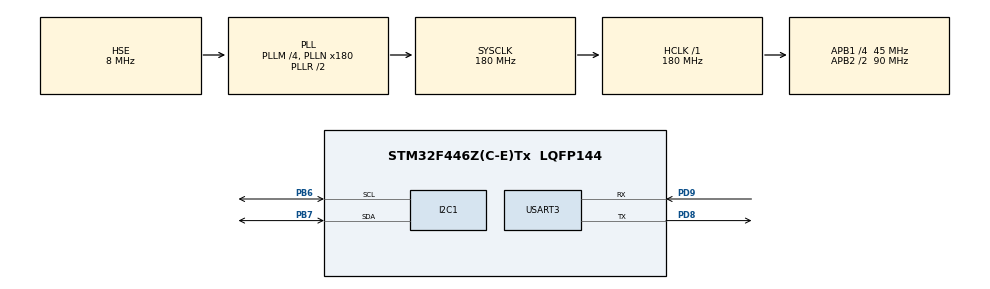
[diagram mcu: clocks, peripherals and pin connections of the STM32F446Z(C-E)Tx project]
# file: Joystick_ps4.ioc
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Mcu.Family=STM32F4
Mcu.Name=STM32F446Z(C-E)Tx
Mcu.Package=LQFP144
NVIC.PriorityGroup=NVIC_PRIORITYGROUP_4
PA13.Mode=Serial_Wire
PA13.Signal=SYS_JTMS-SWDIO
PA14.Mode=Serial_Wire
PA14.Signal=SYS_JTCK-SWCLK
PB6.Mode=I2C
PB6.Signal=I2C1_SCL
PB7.Mode=I2C
PB7.Signal=I2C1_SDA
PC14-OSC32_IN.Mode=LSE-External-Oscillator
PC14-OSC32_IN.Signal=RCC_OSC32_IN
PC15-OSC32_OUT.Mode=LSE-External-Oscillator
PC15-OSC32_OUT.Signal=RCC_OSC32_OUT
PD8.Mode=Asynchronous
PD8.Signal=USART3_TX
PD9.Mode=Asynchronous
PD9.Signal=USART3_RX
PH0-OSC_IN.Mode=HSE-External-Oscillator
PH0-OSC_IN.Signal=RCC_OSC_IN
PH1-OSC_OUT.Mode=HSE-External-Oscillator
PH1-OSC_OUT.Signal=RCC_OSC_OUT
ProjectManager.HeapSize=0x200
ProjectManager.StackSize=0x400
ProjectManager.TargetToolchain=STM32CubeIDE
RCC.48MHZClocksFreq_Value=24000000
RCC.AHBFreq_Value=180000000
RCC.APB1CLKDivider=RCC_HCLK_DIV4
RCC.APB1Freq_Value=45000000
RCC.APB1TimFreq_Value=90000000
RCC.APB2CLKDivider=RCC_HCLK_DIV2
RCC.APB2Freq_Value=90000000
RCC.APB2TimFreq_Value=180000000
RCC.CortexFreq_Value=180000000
RCC.HCLKFreq_Value=180000000
RCC.HSE_VALUE=8000000
RCC.HSI_VALUE=16000000
RCC.PLLM=4
RCC.PLLMUL=RCC_PLL_MUL9
RCC.PLLN=180
RCC.PLLQ=7
RCC.PLLSourceVirtual=RCC_PLLSOURCE_HSE
RCC.PRESCALERUSB=RCC_USBCLKSOURCE_PLL_DIV1_5
RCC.SYSCLKFreq_VALUE=180000000
RCC.SYSCLKSource=RCC_SYSCLKSOURCE_PLLRCLK
RCC.SYSCLKSourceVirtual=RCC_SYSCLKSOURCE_PLLCLK
RCC.USBFreq_Value=51428571.428571425
RCC.VCOOutputFreq_Value=360000000
USART3.VirtualMode=VM_ASYNC
board=NUCLEO-F446ZE

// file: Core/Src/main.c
/* USER CODE BEGIN Header */
/**
  ******************************************************************************
  * @file           : main.c
  * @brief          : Main program body
  ******************************************************************************
  */
/* USER CODE END Header */

#include "main.h"
#include <stdio.h>
#include <string.h>

I2C_HandleTypeDef hi2c1;
UART_HandleTypeDef huart3;

/* USER CODE BEGIN PV */
#define DATA_SIZE 8   // 4 joystick + 4 buttons

uint8_t slave_addr = 0x05;
uint8_t data[DATA_SIZE];

int l_x = 0, l_y = 0, r_x = 0, r_y = 0;
/* USER CODE END PV */

void SystemClock_Config(void);
static void MX_GPIO_Init(void);
static void MX_USART3_UART_Init(void);
static void MX_I2C1_Init(void);

/* USER CODE BEGIN PFP */
long map(long x, long in_min, long in_max, long out_min, long out_max);
/* USER CODE END PFP */

int main(void)
{
  HAL_Init();
  SystemClock_Config();

  MX_GPIO_Init();
  MX_USART3_UART_Init();
  MX_I2C1_Init();

  char buffer[128];

  sprintf(buffer, "\r\n--- System Started ---\r\nReading Slave 0x%02X\r\n", slave_addr);
  HAL_UART_Transmit(&huart3, (uint8_t*)buffer, strlen(buffer), 100);

  while (1)
  {
    HAL_StatusTypeDef status = HAL_I2C_Master_Receive(
        &hi2c1,
        (uint16_t)(slave_addr << 1),
        data,
        DATA_SIZE,
        100
    );

    if (status == HAL_OK)
    {
      /* Map joystick values */
      l_x = map(data[0], 0, 255, -127, 127);
      l_y = map(data[1], 0, 255, -127, 127);
      r_x = map(data[2], 0, 255, -127, 127);
      r_y = map(data[3], 0, 255, -127, 127);

      /* Buttons */
      uint8_t L1 = data[4];
      uint8_t L2 = (data[5] > 50) ? 1 : 0;
      uint8_t R1 = data[6];
      uint8_t R2 = (data[7] > 50) ? 1 : 0;

      sprintf(buffer,
              "LX:%4d | LY:%4d | RX:%4d | RY:%4d | L1:%d L2:%d R1:%d R2:%d\r\n",
              l_x, l_y, r_x, r_y, L1, L2, R1, R2);
    }
    else
    {
      sprintf(buffer, "I2C Error! Code: %d\r\n", status);
    }

    HAL_UART_Transmit(&huart3, (uint8_t*)buffer, strlen(buffer), 100);

    HAL_Delay(1000);  // 100ms delay
  }
}

/* ================= CLOCK CONFIG (FIXED ERROR) ================= */
void SystemClock_Config(void)
{
  RCC_OscInitTypeDef RCC_OscInitStruct = {0};
  RCC_ClkInitTypeDef RCC_ClkInitStruct = {0};

  __HAL_RCC_PWR_CLK_ENABLE();
  __HAL_PWR_VOLTAGESCALING_CONFIG(PWR_REGULATOR_VOLTAGE_SCALE1);

  RCC_OscInitStruct.OscillatorType = RCC_OSCILLATORTYPE_HSE;
  RCC_OscInitStruct.HSEState = RCC_HSE_ON;
  RCC_OscInitStruct.PLL.PLLState = RCC_PLL_ON;
  RCC_OscInitStruct.PLL.PLLSource = RCC_PLLSOURCE_HSE;
  RCC_OscInitStruct.PLL.PLLM = 4;
  RCC_OscInitStruct.PLL.PLLN = 180;
  RCC_OscInitStruct.PLL.PLLP = RCC_PLLP_DIV2;
  RCC_OscInitStruct.PLL.PLLQ = 7;
  RCC_OscInitStruct.PLL.PLLR = 2;

  if (HAL_RCC_OscConfig(&RCC_OscInitStruct) != HAL_OK)
    Error_Handler();

  if (HAL_PWREx_EnableOverDrive() != HAL_OK)
    Error_Handler();

  RCC_ClkInitStruct.ClockType = RCC_CLOCKTYPE_HCLK |
                                RCC_CLOCKTYPE_SYSCLK |
                                RCC_CLOCKTYPE_PCLK1 |
                                RCC_CLOCKTYPE_PCLK2;

  RCC_ClkInitStruct.SYSCLKSource = RCC_SYSCLKSOURCE_PLLRCLK;
  RCC_ClkInitStruct.AHBCLKDivider = RCC_SYSCLK_DIV1;
  RCC_ClkInitStruct.APB1CLKDivider = RCC_HCLK_DIV4;
  RCC_ClkInitStruct.APB2CLKDivider = RCC_HCLK_DIV2;

  if (HAL_RCC_ClockConfig(&RCC_ClkInitStruct, FLASH_LATENCY_5) != HAL_OK)
    Error_Handler();
}

/* ================= I2C ================= */
static void MX_I2C1_Init(void)
{
  hi2c1.Instance = I2C1;
  hi2c1.Init.ClockSpeed = 100000;
  hi2c1.Init.DutyCycle = I2C_DUTYCYCLE_2;
  hi2c1.Init.OwnAddress1 = 0x05;
  hi2c1.Init.AddressingMode = I2C_ADDRESSINGMODE_7BIT;
  hi2c1.Init.DualAddressMode = I2C_DUALADDRESS_DISABLE;
  hi2c1.Init.OwnAddress2 = 0;
  hi2c1.Init.GeneralCallMode = I2C_GENERALCALL_DISABLE;
  hi2c1.Init.NoStretchMode = I2C_NOSTRETCH_DISABLE;

  if (HAL_I2C_Init(&hi2c1) != HAL_OK)
    Error_Handler();
}

/* ================= UART ================= */
static void MX_USART3_UART_Init(void)
{
  huart3.Instance = USART3;
  huart3.Init.BaudRate = 115200;
  huart3.Init.WordLength = UART_WORDLENGTH_8B;
  huart3.Init.StopBits = UART_STOPBITS_1;
  huart3.Init.Parity = UART_PARITY_NONE;
  huart3.Init.Mode = UART_MODE_TX_RX;
  huart3.Init.HwFlowCtl = UART_HWCONTROL_NONE;
  huart3.Init.OverSampling = UART_OVERSAMPLING_16;

  if (HAL_UART_Init(&huart3) != HAL_OK)
    Error_Handler();
}

/* ================= GPIO ================= */
static void MX_GPIO_Init(void)
{
  __HAL_RCC_GPIOC_CLK_ENABLE();
  __HAL_RCC_GPIOH_CLK_ENABLE();
  __HAL_RCC_GPIOD_CLK_ENABLE();
  __HAL_RCC_GPIOA_CLK_ENABLE();
  __HAL_RCC_GPIOB_CLK_ENABLE();
}

/* ================= MAP FUNCTION ================= */
long map(long x, long in_min, long in_max, long out_min, long out_max)
{
  return (x - in_min) * (out_max - out_min) /
         (in_max - in_min) + out_min;
}

/* ================= ERROR HANDLER ================= */
void Error_Handler(void)
{
  __disable_irq();
  while (1)
  {
  }
}
